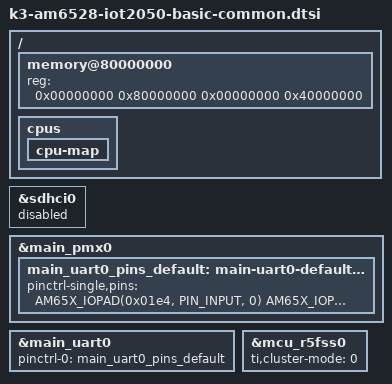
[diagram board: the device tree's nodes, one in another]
#include "k3-am65-iot2050-common.dtsi"
/ {
	memory@80000000 {
		device_type = "memory";
		reg = <0x00000000 0x80000000 0x00000000 0x40000000>;
	};
	cpus {
		cpu-map {
			/delete-node/ cluster1;
		};
		/delete-node/ cpu@100;
		/delete-node/ cpu@101;
	};
	/delete-node/ l2-cache1;
};
&sdhci0 {
	status = "disabled";
};
&main_pmx0 {
	main_uart0_pins_default: main-uart0-default-pins {
		pinctrl-single,pins = <
			AM65X_IOPAD(0x01e4, PIN_INPUT,  0)   
			AM65X_IOPAD(0x01e8, PIN_OUTPUT, 0)   
			AM65X_IOPAD(0x01ec, PIN_INPUT,  0)   
			AM65X_IOPAD(0x01f0, PIN_OUTPUT, 0)   
			AM65X_IOPAD(0x0188, PIN_INPUT,  1)   
			AM65X_IOPAD(0x018c, PIN_INPUT,  1)   
			AM65X_IOPAD(0x0190, PIN_OUTPUT, 1)   
			AM65X_IOPAD(0x0194, PIN_INPUT,  1)   
		>;
	};
};
&main_uart0 {
	status = "okay";
	pinctrl-names = "default";
	pinctrl-0 = <&main_uart0_pins_default>;
};
&mcu_r5fss0 {
	ti,cluster-mode = <0>;
};
